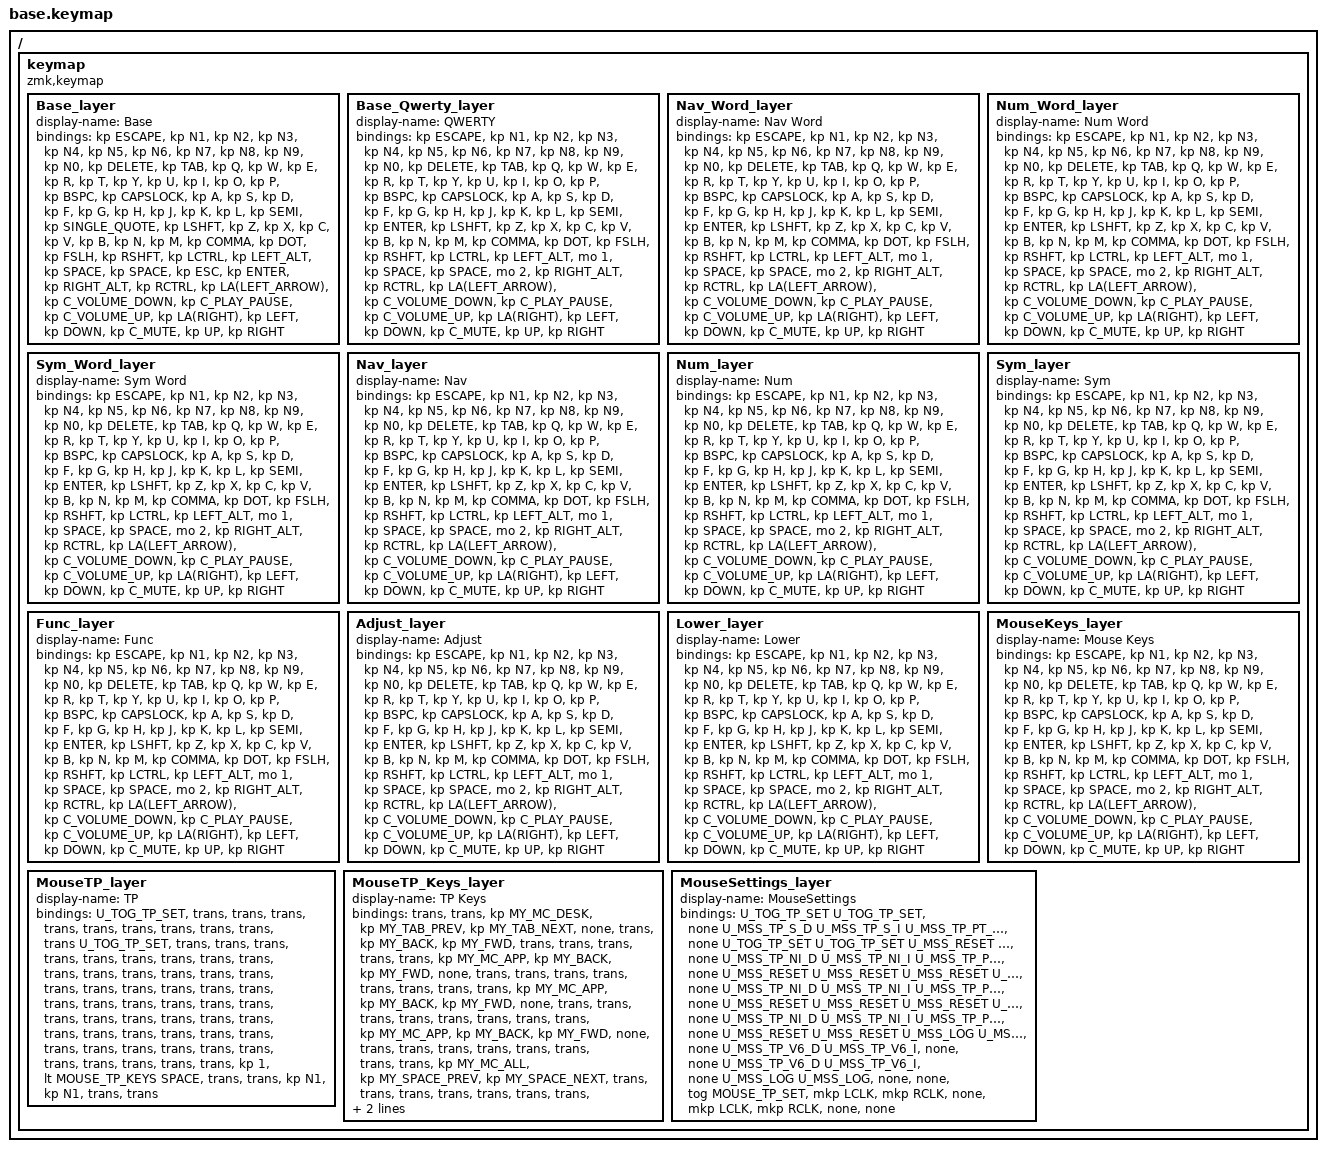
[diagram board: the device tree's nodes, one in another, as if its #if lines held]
/*
 * Copyright (c) 2020 The ZMK Contributors
 *
 * SPDX-License-Identifier: MIT
 */

// Define layer numbers
#define BASE 0
#define BASE_QWERTY 1
#define NAV_WORD 2
#define NUM_WORD 3
#define SYM_WORD 4
#define NAV 5
#define NUM 6
#define SYM 7
#define FUNC 8
#define ADJUST 9
#define LOWER 10
#define MOUSE_KEYS 11
#define MOUSE_TP 12
#define MOUSE_TP_KEYS 13
#define MOUSE_TP_SET 14

#ifdef HAS_UROB
  #define HAS_TRI_STATE
  #define HAS_NUM_WORD
#endif

// ZMK includes
#include <behaviors.dtsi>
#include <dt-bindings/zmk/keys.h>
#include <dt-bindings/zmk/bt.h>
#include <dt-bindings/zmk/rgb.h>
#include <dt-bindings/zmk/ext_power.h>


// Personal includes
#include "includes/custom_keycodes.dtsi"
#include "includes/settings.dtsi"
//#include "includes/conditional_layers.dtsi"
#include "includes/macros.dtsi"
//#include "includes/combos.dtsi"
//#include "includes/behaviours_homerow_mods.dtsi"
//#include "includes/behaviours_mod_morph.dtsi"
//#include "includes/behaviours_other.dtsi"
#include "includes/mouse_keys.dtsi"
#include "includes/mouse_tp.dtsi"
#include "includes/mouse_tp_badjeff_input_listener.dtsi"


#ifdef HAS_MOUSE_TP
  #define U_TOG_TP_SET &tog MOUSE_TP_SET
#else
  #define U_TOG_TP_SET &none
#endif  // HAS_MOUSE_TP


/ {

  keymap {
    compatible = "zmk,keymap";

    Base_layer {
      display-name = "Base";
      bindings = <
&kp ESCAPE    &kp N1              &kp N2             &kp N3            &kp N4           &kp N5         &kp N6     &kp N7    &kp N8      &kp N9   &kp N0         &kp DELETE
&kp TAB       &kp Q               &kp W              &kp E             &kp R            &kp T          &kp Y      &kp U     &kp I       &kp O    &kp P          &kp BSPC
&kp CAPSLOCK  &kp A               &kp S              &kp D             &kp F            &kp G          &kp H      &kp J     &kp K       &kp L    &kp SEMI       &kp SINGLE_QUOTE
&kp LSHFT     &kp Z               &kp X              &kp C             &kp V            &kp B          &kp N      &kp M     &kp COMMA   &kp DOT  &kp FSLH       &kp RSHFT
&kp LCTRL     &kp LEFT_ALT                                             &kp SPACE        &kp SPACE      &kp ESC    &kp ENTER                      &kp RIGHT_ALT  &kp RCTRL
              &kp LA(LEFT_ARROW)  &kp C_VOLUME_DOWN  &kp C_PLAY_PAUSE  &kp C_VOLUME_UP  &kp LA(RIGHT)  &kp LEFT   &kp DOWN  &kp C_MUTE  &kp UP   &kp RIGHT

      >;
     //  sensor-bindings = <&inc_dec_kp C_VOL_DN C_VOL_UP &inc_dec_kp C_PREV C_NEXT>;
    };

    Base_Qwerty_layer {
      display-name = "QWERTY";
      bindings = <
&kp ESCAPE    &kp N1              &kp N2             &kp N3            &kp N4           &kp N5         &kp N6     &kp N7    &kp N8      &kp N9   &kp N0         &kp DELETE
&kp TAB       &kp Q               &kp W              &kp E             &kp R            &kp T          &kp Y      &kp U     &kp I       &kp O    &kp P          &kp BSPC
&kp CAPSLOCK  &kp A               &kp S              &kp D             &kp F            &kp G          &kp H      &kp J     &kp K       &kp L    &kp SEMI       &kp ENTER
&kp LSHFT     &kp Z               &kp X              &kp C             &kp V            &kp B          &kp N      &kp M     &kp COMMA   &kp DOT  &kp FSLH       &kp RSHFT
&kp LCTRL     &kp LEFT_ALT                                             &mo 1            &kp SPACE      &kp SPACE  &mo 2                          &kp RIGHT_ALT  &kp RCTRL
              &kp LA(LEFT_ARROW)  &kp C_VOLUME_DOWN  &kp C_PLAY_PAUSE  &kp C_VOLUME_UP  &kp LA(RIGHT)  &kp LEFT   &kp DOWN  &kp C_MUTE  &kp UP   &kp RIGHT
      >;
    };

    Nav_Word_layer {
      display-name = "Nav Word";
      bindings = <
&kp ESCAPE    &kp N1              &kp N2             &kp N3            &kp N4           &kp N5         &kp N6     &kp N7    &kp N8      &kp N9   &kp N0         &kp DELETE
&kp TAB       &kp Q               &kp W              &kp E             &kp R            &kp T          &kp Y      &kp U     &kp I       &kp O    &kp P          &kp BSPC
&kp CAPSLOCK  &kp A               &kp S              &kp D             &kp F            &kp G          &kp H      &kp J     &kp K       &kp L    &kp SEMI       &kp ENTER
&kp LSHFT     &kp Z               &kp X              &kp C             &kp V            &kp B          &kp N      &kp M     &kp COMMA   &kp DOT  &kp FSLH       &kp RSHFT
&kp LCTRL     &kp LEFT_ALT                                             &mo 1            &kp SPACE      &kp SPACE  &mo 2                          &kp RIGHT_ALT  &kp RCTRL
              &kp LA(LEFT_ARROW)  &kp C_VOLUME_DOWN  &kp C_PLAY_PAUSE  &kp C_VOLUME_UP  &kp LA(RIGHT)  &kp LEFT   &kp DOWN  &kp C_MUTE  &kp UP   &kp RIGHT
      >;
     //  sensor-bindings = <&inc_dec_kp C_BRI_DN C_BRI_UP &inc_dec_kp LEFT RIGHT>;
    };

    Num_Word_layer {
      display-name = "Num Word";
      bindings = <
&kp ESCAPE    &kp N1              &kp N2             &kp N3            &kp N4           &kp N5         &kp N6     &kp N7    &kp N8      &kp N9   &kp N0         &kp DELETE
&kp TAB       &kp Q               &kp W              &kp E             &kp R            &kp T          &kp Y      &kp U     &kp I       &kp O    &kp P          &kp BSPC
&kp CAPSLOCK  &kp A               &kp S              &kp D             &kp F            &kp G          &kp H      &kp J     &kp K       &kp L    &kp SEMI       &kp ENTER
&kp LSHFT     &kp Z               &kp X              &kp C             &kp V            &kp B          &kp N      &kp M     &kp COMMA   &kp DOT  &kp FSLH       &kp RSHFT
&kp LCTRL     &kp LEFT_ALT                                             &mo 1            &kp SPACE      &kp SPACE  &mo 2                          &kp RIGHT_ALT  &kp RCTRL
              &kp LA(LEFT_ARROW)  &kp C_VOLUME_DOWN  &kp C_PLAY_PAUSE  &kp C_VOLUME_UP  &kp LA(RIGHT)  &kp LEFT   &kp DOWN  &kp C_MUTE  &kp UP   &kp RIGHT
      >;
     //  sensor-bindings = <&inc_dec_kp C_BRI_DN C_BRI_UP &inc_dec_kp LEFT RIGHT>;
    };

    Sym_Word_layer {
      display-name = "Sym Word";
      bindings = <
&kp ESCAPE    &kp N1              &kp N2             &kp N3            &kp N4           &kp N5         &kp N6     &kp N7    &kp N8      &kp N9   &kp N0         &kp DELETE
&kp TAB       &kp Q               &kp W              &kp E             &kp R            &kp T          &kp Y      &kp U     &kp I       &kp O    &kp P          &kp BSPC
&kp CAPSLOCK  &kp A               &kp S              &kp D             &kp F            &kp G          &kp H      &kp J     &kp K       &kp L    &kp SEMI       &kp ENTER
&kp LSHFT     &kp Z               &kp X              &kp C             &kp V            &kp B          &kp N      &kp M     &kp COMMA   &kp DOT  &kp FSLH       &kp RSHFT
&kp LCTRL     &kp LEFT_ALT                                             &mo 1            &kp SPACE      &kp SPACE  &mo 2                          &kp RIGHT_ALT  &kp RCTRL
              &kp LA(LEFT_ARROW)  &kp C_VOLUME_DOWN  &kp C_PLAY_PAUSE  &kp C_VOLUME_UP  &kp LA(RIGHT)  &kp LEFT   &kp DOWN  &kp C_MUTE  &kp UP   &kp RIGHT
      >;
     //  sensor-bindings = <&inc_dec_kp C_BRI_DN C_BRI_UP &inc_dec_kp LEFT RIGHT>;
    };

    Nav_layer {
      display-name = "Nav";
      bindings = <
&kp ESCAPE    &kp N1              &kp N2             &kp N3            &kp N4           &kp N5         &kp N6     &kp N7    &kp N8      &kp N9   &kp N0         &kp DELETE
&kp TAB       &kp Q               &kp W              &kp E             &kp R            &kp T          &kp Y      &kp U     &kp I       &kp O    &kp P          &kp BSPC
&kp CAPSLOCK  &kp A               &kp S              &kp D             &kp F            &kp G          &kp H      &kp J     &kp K       &kp L    &kp SEMI       &kp ENTER
&kp LSHFT     &kp Z               &kp X              &kp C             &kp V            &kp B          &kp N      &kp M     &kp COMMA   &kp DOT  &kp FSLH       &kp RSHFT
&kp LCTRL     &kp LEFT_ALT                                             &mo 1            &kp SPACE      &kp SPACE  &mo 2                          &kp RIGHT_ALT  &kp RCTRL
              &kp LA(LEFT_ARROW)  &kp C_VOLUME_DOWN  &kp C_PLAY_PAUSE  &kp C_VOLUME_UP  &kp LA(RIGHT)  &kp LEFT   &kp DOWN  &kp C_MUTE  &kp UP   &kp RIGHT
      >;
     //  sensor-bindings = <&inc_dec_kp C_BRI_DN C_BRI_UP &inc_dec_kp LEFT RIGHT>;
    };

    Num_layer {
      display-name = "Num";
      bindings = <
&kp ESCAPE    &kp N1              &kp N2             &kp N3            &kp N4           &kp N5         &kp N6     &kp N7    &kp N8      &kp N9   &kp N0         &kp DELETE
&kp TAB       &kp Q               &kp W              &kp E             &kp R            &kp T          &kp Y      &kp U     &kp I       &kp O    &kp P          &kp BSPC
&kp CAPSLOCK  &kp A               &kp S              &kp D             &kp F            &kp G          &kp H      &kp J     &kp K       &kp L    &kp SEMI       &kp ENTER
&kp LSHFT     &kp Z               &kp X              &kp C             &kp V            &kp B          &kp N      &kp M     &kp COMMA   &kp DOT  &kp FSLH       &kp RSHFT
&kp LCTRL     &kp LEFT_ALT                                             &mo 1            &kp SPACE      &kp SPACE  &mo 2                          &kp RIGHT_ALT  &kp RCTRL
              &kp LA(LEFT_ARROW)  &kp C_VOLUME_DOWN  &kp C_PLAY_PAUSE  &kp C_VOLUME_UP  &kp LA(RIGHT)  &kp LEFT   &kp DOWN  &kp C_MUTE  &kp UP   &kp RIGHT
      >;
     //  sensor-bindings = <&inc_dec_kp C_BRI_DN C_BRI_UP &inc_dec_kp LEFT RIGHT>;
    };

    Sym_layer {
      display-name = "Sym";
      bindings = <
&kp ESCAPE    &kp N1              &kp N2             &kp N3            &kp N4           &kp N5         &kp N6     &kp N7    &kp N8      &kp N9   &kp N0         &kp DELETE
&kp TAB       &kp Q               &kp W              &kp E             &kp R            &kp T          &kp Y      &kp U     &kp I       &kp O    &kp P          &kp BSPC
&kp CAPSLOCK  &kp A               &kp S              &kp D             &kp F            &kp G          &kp H      &kp J     &kp K       &kp L    &kp SEMI       &kp ENTER
&kp LSHFT     &kp Z               &kp X              &kp C             &kp V            &kp B          &kp N      &kp M     &kp COMMA   &kp DOT  &kp FSLH       &kp RSHFT
&kp LCTRL     &kp LEFT_ALT                                             &mo 1            &kp SPACE      &kp SPACE  &mo 2                          &kp RIGHT_ALT  &kp RCTRL
              &kp LA(LEFT_ARROW)  &kp C_VOLUME_DOWN  &kp C_PLAY_PAUSE  &kp C_VOLUME_UP  &kp LA(RIGHT)  &kp LEFT   &kp DOWN  &kp C_MUTE  &kp UP   &kp RIGHT
      >;
     //  sensor-bindings = <&inc_dec_kp C_BRI_DN C_BRI_UP &inc_dec_kp LEFT RIGHT>;
    };

    Func_layer {
      display-name = "Func";
      bindings = <
&kp ESCAPE    &kp N1              &kp N2             &kp N3            &kp N4           &kp N5         &kp N6     &kp N7    &kp N8      &kp N9   &kp N0         &kp DELETE
&kp TAB       &kp Q               &kp W              &kp E             &kp R            &kp T          &kp Y      &kp U     &kp I       &kp O    &kp P          &kp BSPC
&kp CAPSLOCK  &kp A               &kp S              &kp D             &kp F            &kp G          &kp H      &kp J     &kp K       &kp L    &kp SEMI       &kp ENTER
&kp LSHFT     &kp Z               &kp X              &kp C             &kp V            &kp B          &kp N      &kp M     &kp COMMA   &kp DOT  &kp FSLH       &kp RSHFT
&kp LCTRL     &kp LEFT_ALT                                             &mo 1            &kp SPACE      &kp SPACE  &mo 2                          &kp RIGHT_ALT  &kp RCTRL
              &kp LA(LEFT_ARROW)  &kp C_VOLUME_DOWN  &kp C_PLAY_PAUSE  &kp C_VOLUME_UP  &kp LA(RIGHT)  &kp LEFT   &kp DOWN  &kp C_MUTE  &kp UP   &kp RIGHT
      >;
     //  sensor-bindings = <&inc_dec_kp C_BRI_DN C_BRI_UP &inc_dec_kp LEFT RIGHT>;
    };

    Adjust_layer {
      display-name = "Adjust";
      bindings = <
&kp ESCAPE    &kp N1              &kp N2             &kp N3            &kp N4           &kp N5         &kp N6     &kp N7    &kp N8      &kp N9   &kp N0         &kp DELETE
&kp TAB       &kp Q               &kp W              &kp E             &kp R            &kp T          &kp Y      &kp U     &kp I       &kp O    &kp P          &kp BSPC
&kp CAPSLOCK  &kp A               &kp S              &kp D             &kp F            &kp G          &kp H      &kp J     &kp K       &kp L    &kp SEMI       &kp ENTER
&kp LSHFT     &kp Z               &kp X              &kp C             &kp V            &kp B          &kp N      &kp M     &kp COMMA   &kp DOT  &kp FSLH       &kp RSHFT
&kp LCTRL     &kp LEFT_ALT                                             &mo 1            &kp SPACE      &kp SPACE  &mo 2                          &kp RIGHT_ALT  &kp RCTRL
              &kp LA(LEFT_ARROW)  &kp C_VOLUME_DOWN  &kp C_PLAY_PAUSE  &kp C_VOLUME_UP  &kp LA(RIGHT)  &kp LEFT   &kp DOWN  &kp C_MUTE  &kp UP   &kp RIGHT
      >;
     //  sensor-bindings = <&inc_dec_kp C_BRI_DN C_BRI_UP &inc_dec_kp LEFT RIGHT>;
    };

    Lower_layer {
      display-name = "Lower";
      bindings = <
&kp ESCAPE    &kp N1              &kp N2             &kp N3            &kp N4           &kp N5         &kp N6     &kp N7    &kp N8      &kp N9   &kp N0         &kp DELETE
&kp TAB       &kp Q               &kp W              &kp E             &kp R            &kp T          &kp Y      &kp U     &kp I       &kp O    &kp P          &kp BSPC
&kp CAPSLOCK  &kp A               &kp S              &kp D             &kp F            &kp G          &kp H      &kp J     &kp K       &kp L    &kp SEMI       &kp ENTER
&kp LSHFT     &kp Z               &kp X              &kp C             &kp V            &kp B          &kp N      &kp M     &kp COMMA   &kp DOT  &kp FSLH       &kp RSHFT
&kp LCTRL     &kp LEFT_ALT                                             &mo 1            &kp SPACE      &kp SPACE  &mo 2                          &kp RIGHT_ALT  &kp RCTRL
              &kp LA(LEFT_ARROW)  &kp C_VOLUME_DOWN  &kp C_PLAY_PAUSE  &kp C_VOLUME_UP  &kp LA(RIGHT)  &kp LEFT   &kp DOWN  &kp C_MUTE  &kp UP   &kp RIGHT
      >;
     //  sensor-bindings = <&inc_dec_kp C_BRI_DN C_BRI_UP &inc_dec_kp LEFT RIGHT>;
    };

#ifdef HAS_MOUSE_KEYS
    MouseKeys_layer {
      display-name = "Mouse Keys";
      bindings = <
&kp ESCAPE    &kp N1              &kp N2             &kp N3            &kp N4           &kp N5         &kp N6     &kp N7    &kp N8      &kp N9   &kp N0         &kp DELETE
&kp TAB       &kp Q               &kp W              &kp E             &kp R            &kp T          &kp Y      &kp U     &kp I       &kp O    &kp P          &kp BSPC
&kp CAPSLOCK  &kp A               &kp S              &kp D             &kp F            &kp G          &kp H      &kp J     &kp K       &kp L    &kp SEMI       &kp ENTER
&kp LSHFT     &kp Z               &kp X              &kp C             &kp V            &kp B          &kp N      &kp M     &kp COMMA   &kp DOT  &kp FSLH       &kp RSHFT
&kp LCTRL     &kp LEFT_ALT                                             &mo 1            &kp SPACE      &kp SPACE  &mo 2                          &kp RIGHT_ALT  &kp RCTRL
              &kp LA(LEFT_ARROW)  &kp C_VOLUME_DOWN  &kp C_PLAY_PAUSE  &kp C_VOLUME_UP  &kp LA(RIGHT)  &kp LEFT   &kp DOWN  &kp C_MUTE  &kp UP   &kp RIGHT
      >;
     //  sensor-bindings = <&inc_dec_kp C_BRI_DN C_BRI_UP &inc_dec_kp LEFT RIGHT>;
    };
#endif

#ifdef HAS_MOUSE_TP
    MouseTP_layer {
      display-name = "TP";
      bindings = <
// ╭────────────────────────┬────────────────────────┬────────────────────────┬────────────────────────┬────────────────────────┬────────────────────────╮    ╭────────────────────────┬────────────────────────┬────────────────────────┬────────────────────────┬────────────────────────┬────────────────────────╮
     U_TOG_TP_SET             &trans                   &trans                   &trans                   &trans                   &trans                        &trans                   &trans                   &trans                    &trans                   &trans                    U_TOG_TP_SET
// ├────────────────────────┼────────────────────────┼────────────────────────┼────────────────────────┼────────────────────────┼────────────────────────┤    ├────────────────────────┼────────────────────────┼────────────────────────┼────────────────────────┼────────────────────────┼────────────────────────┤
     &trans                   &trans                   &trans                   &trans                   &trans                   &trans                        &trans                   &trans                   &trans                    &trans                   &trans                    &trans
     &trans                   &trans                   &trans                   &trans                   &trans                   &trans                        &trans                   &trans                   &trans                    &trans                   &trans                    &trans
     &trans                   &trans                   &trans                   &trans                   &trans                   &trans                        &trans                   &trans                   &trans                    &trans                   &trans                    &trans
// ├────────────────────────┼────────────────────────┼────────────────────────┼────────────────────────┼────────────────────────┼────────────────────────┤    ├────────────────────────┼────────────────────────┼────────────────────────┼────────────────────────┼────────────────────────┼────────────────────────┤
     &trans                   &trans                   &trans                   &trans                   &trans                   &trans                        &trans                   &trans                   &trans                    &trans                   &trans                    &trans
// ╰────────────────────────┴────────────────────────┴────────────────────────┴────────────────────────┼────────────────────────┼────────────────────────┤    ├────────────────────────┼────────────────────────┼────────────────────────┼────────────────────────┴────────────────────────┼────────────────────────╯
                              &trans                   &trans                   &kp 1       &lt MOUSE_TP_KEYS SPACE  &trans                        &trans                    &kp N1      &kp N1          &trans                   &trans
//                                                                            ╰────────────────────────┴────────────────────────┴────────────────────────╯    ╰────────────────────────┴────────────────────────┴────────────────────────╯
      >;
     //  sensor-bindings = <&inc_dec_kp C_BRI_DN C_BRI_UP &inc_dec_kp LEFT RIGHT>;
    };

    MouseTP_Keys_layer {
      display-name = "TP Keys";
      bindings = <
// ╭────────────────────────┬────────────────────────┬────────────────────────┬────────────────────────┬────────────────────────┬────────────────────────╮    ╭────────────────────────┬────────────────────────┬────────────────────────┬────────────────────────┬────────────────────────┬────────────────────────╮
     &trans                   &trans                   &kp MY_MC_DESK           &kp MY_TAB_PREV          &kp MY_TAB_NEXT          &none                         &trans                   &kp MY_BACK               &kp MY_FWD               &trans                    &trans                  &trans
// ├────────────────────────┼────────────────────────┼────────────────────────┼────────────────────────┼────────────────────────┼────────────────────────┤    ├────────────────────────┼────────────────────────┼────────────────────────┼────────────────────────┼────────────────────────┼────────────────────────┤
     &trans                   &trans                   &kp MY_MC_APP            &kp MY_BACK              &kp MY_FWD               &none                         &trans                   &trans                    &trans                   &trans                    &trans                  &trans
     &trans                   &trans                   &kp MY_MC_APP            &kp MY_BACK              &kp MY_FWD               &none                         &trans                   &trans                    &trans                   &trans                    &trans                  &trans
     &trans                   &trans                   &kp MY_MC_APP            &kp MY_BACK              &kp MY_FWD               &none                         &trans                   &trans                    &trans                   &trans                    &trans                  &trans
// ├────────────────────────┼────────────────────────┼────────────────────────┼────────────────────────┼────────────────────────┼────────────────────────┤    ├────────────────────────┼────────────────────────┼────────────────────────┼────────────────────────┼────────────────────────┼────────────────────────┤
     &trans                   &trans                   &kp MY_MC_ALL            &kp MY_SPACE_PREV        &kp MY_SPACE_NEXT        &trans                        &trans                   &trans                    &trans                   &trans                    &trans                  &trans
// ╰────────────────────────┴────────────────────────┴────────────────────────┴────────────────────────┼────────────────────────┼────────────────────────┤    ├────────────────────────┼────────────────────────┼────────────────────────┼────────────────────────┴────────────────────────┼────────────────────────╯
                               &trans                   &trans                  &kp N1 &trans                   &trans                        &trans                    &trans                   &trans                   &trans                    &trans
//                                                                            ╰────────────────────────┴────────────────────────┴────────────────────────╯    ╰────────────────────────┴────────────────────────┴────────────────────────╯
      >;
     //  sensor-bindings = <&inc_dec_kp C_BRI_DN C_BRI_UP &inc_dec_kp LEFT RIGHT>;
    };

    MouseSettings_layer {
      display-name = "MouseSettings";
      bindings = <
// ╭────────────────────────┬────────────────────────┬────────────────────────┬────────────────────────┬────────────────────────┬────────────────────────╮    ╭────────────────────────┬────────────────────────┬────────────────────────┬────────────────────────┬────────────────────────┬────────────────────────╮
     U_TOG_TP_SET             U_TOG_TP_SET             &none                    U_MSS_TP_S_D             U_MSS_TP_S_I             U_MSS_TP_PT_I                 U_MSS_TP_PT_I            U_MSS_TP_S_D             U_MSS_TP_S_I             &none                    U_TOG_TP_SET             U_TOG_TP_SET
// ├────────────────────────┼────────────────────────┼────────────────────────┼────────────────────────┼────────────────────────┼────────────────────────┤    ├────────────────────────┼────────────────────────┼────────────────────────┼────────────────────────┼────────────────────────┼────────────────────────┤
     U_MSS_RESET              U_MSS_RESET              &none                    U_MSS_TP_NI_D            U_MSS_TP_NI_I            U_MSS_TP_PT_D                 U_MSS_TP_PT_D            U_MSS_TP_NI_D            U_MSS_TP_NI_I            &none                    U_MSS_RESET               U_MSS_RESET
     U_MSS_RESET              U_MSS_RESET              &none                    U_MSS_TP_NI_D            U_MSS_TP_NI_I            U_MSS_TP_PT_D                 U_MSS_TP_PT_D            U_MSS_TP_NI_D            U_MSS_TP_NI_I            &none                    U_MSS_RESET               U_MSS_RESET
     U_MSS_RESET              U_MSS_RESET              &none                    U_MSS_TP_NI_D            U_MSS_TP_NI_I            U_MSS_TP_PT_D                 U_MSS_TP_PT_D            U_MSS_TP_NI_D            U_MSS_TP_NI_I            &none                    U_MSS_RESET               U_MSS_RESET
// ├────────────────────────┼────────────────────────┼────────────────────────┼────────────────────────┼────────────────────────┼────────────────────────┤    ├────────────────────────┼────────────────────────┼────────────────────────┼────────────────────────┼────────────────────────┼────────────────────────┤
     U_MSS_LOG                U_MSS_LOG                &none                    U_MSS_TP_V6_D            U_MSS_TP_V6_I            &none                         &none                    U_MSS_TP_V6_D            U_MSS_TP_V6_I            &none                    U_MSS_LOG                 U_MSS_LOG
// ╰────────────────────────┴────────────────────────┴────────────────────────┴────────────────────────┼────────────────────────┼────────────────────────┤    ├────────────────────────┼────────────────────────┼────────────────────────┼────────────────────────┴────────────────────────┼────────────────────────╯
                               &none                    &none                   &tog MOUSE_TP_SET        &mkp LCLK                &mkp RCLK                     &none                    &mkp LCLK                &mkp RCLK                &none                    &none
//                                                                            ╰────────────────────────┴────────────────────────┴────────────────────────╯    ╰────────────────────────┴────────────────────────┴────────────────────────╯
      >;
     //  sensor-bindings = <&inc_dec_kp C_BRI_DN C_BRI_UP &inc_dec_kp LEFT RIGHT>;
    };
#endif
  };

};
